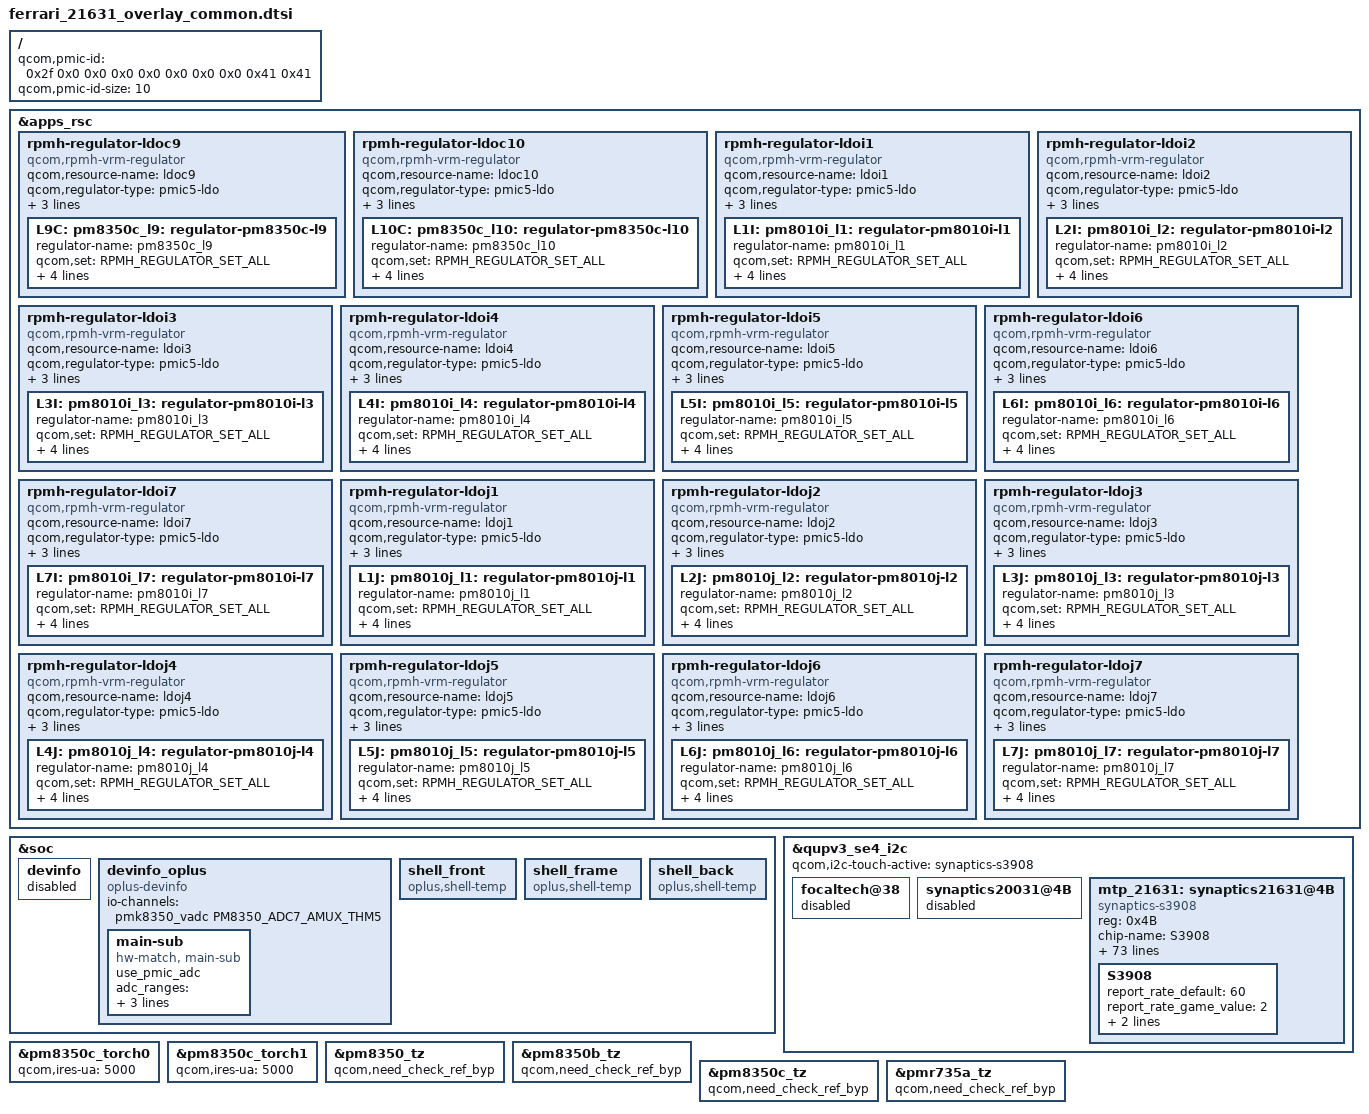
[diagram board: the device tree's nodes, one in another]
/* Waipio configurations for PM8010I and PM8010J connected via SPMI */

#include <dt-bindings/regulator/qcom,rpmh-regulator-levels.h>

/ {
	qcom,pmic-id = <0x2f 0x0 0x0 0x0 0x0 0x0 0x0 0x0 0x41 0x41>;
	qcom,pmic-id-size = <10>;
};

&apps_rsc {

    rpmh-regulator-ldoc9 {
		compatible = "qcom,rpmh-vrm-regulator";
		qcom,resource-name = "ldoc9";
		qcom,regulator-type = "pmic5-ldo";
		qcom,supported-modes =
			<RPMH_REGULATOR_MODE_LPM
			 RPMH_REGULATOR_MODE_HPM>;
		qcom,mode-threshold-currents = <0 10000>;
		L9C: pm8350c_l9: regulator-pm8350c-l9 {
			regulator-name = "pm8350c_l9";
			qcom,set = <RPMH_REGULATOR_SET_ALL>;
			regulator-min-microvolt = <2800000>;
			regulator-max-microvolt = <3008000>;
			qcom,init-voltage = <2800000>;
			qcom,init-mode = <RPMH_REGULATOR_MODE_HPM>;
		};
	};

    rpmh-regulator-ldoc10 {
		compatible = "qcom,rpmh-vrm-regulator";
		qcom,resource-name = "ldoc10";
		qcom,regulator-type = "pmic5-ldo";
		qcom,supported-modes =
			<RPMH_REGULATOR_MODE_LPM
			 RPMH_REGULATOR_MODE_HPM>;
		qcom,mode-threshold-currents = <0 30000>;
		L10C: pm8350c_l10: regulator-pm8350c-l10 {
			regulator-name = "pm8350c_l10";
			qcom,set = <RPMH_REGULATOR_SET_ALL>;
			regulator-min-microvolt = <1104000>;
			regulator-max-microvolt = <1104000>;
			qcom,init-voltage = <1104000>;
			qcom,init-mode = <RPMH_REGULATOR_MODE_HPM>;
		};
	};

	rpmh-regulator-ldoi1 {
	    compatible = "qcom,rpmh-vrm-regulator";
	    qcom,resource-name = "ldoi1";
	    qcom,regulator-type = "pmic5-ldo";
	    qcom,supported-modes =
	        <RPMH_REGULATOR_MODE_LPM
	         RPMH_REGULATOR_MODE_HPM>;
	    qcom,mode-threshold-currents = <0 30000>;
	    L1I: pm8010i_l1: regulator-pm8010i-l1 {
	        regulator-name = "pm8010i_l1";
	        qcom,set = <RPMH_REGULATOR_SET_ALL>;
	        regulator-min-microvolt = <1104000>;
	        regulator-max-microvolt = <1204000>;
	        qcom,init-voltage = <1150000>;
	        qcom,init-mode = <RPMH_REGULATOR_MODE_HPM>;
	    };
	};

	rpmh-regulator-ldoi2 {
		compatible = "qcom,rpmh-vrm-regulator";
		qcom,resource-name = "ldoi2";
		qcom,regulator-type = "pmic5-ldo";
		qcom,supported-modes =
			<RPMH_REGULATOR_MODE_LPM
			 RPMH_REGULATOR_MODE_HPM>;
		qcom,mode-threshold-currents = <0 30000>;
		L2I: pm8010i_l2: regulator-pm8010i-l2 {
			regulator-name = "pm8010i_l2";
			qcom,set = <RPMH_REGULATOR_SET_ALL>;
			regulator-min-microvolt = <1056000>;
			regulator-max-microvolt = <1260000>;
			qcom,init-voltage = <1056000>;
			qcom,init-mode = <RPMH_REGULATOR_MODE_HPM>;
		};
	};

	rpmh-regulator-ldoi3 {
		compatible = "qcom,rpmh-vrm-regulator";
		qcom,resource-name = "ldoi3";
		qcom,regulator-type = "pmic5-ldo";
		qcom,supported-modes =
			<RPMH_REGULATOR_MODE_LPM
			 RPMH_REGULATOR_MODE_HPM>;
		qcom,mode-threshold-currents = <0 10000>;
		L3I: pm8010i_l3: regulator-pm8010i-l3 {
			regulator-name = "pm8010i_l3";
			qcom,set = <RPMH_REGULATOR_SET_ALL>;
			regulator-min-microvolt = <2700000>;
			regulator-max-microvolt = <2904000>;
			qcom,init-voltage = <2800000>;
			qcom,init-mode = <RPMH_REGULATOR_MODE_HPM>;
		};
	};

	rpmh-regulator-ldoi4 {
		compatible = "qcom,rpmh-vrm-regulator";
		qcom,resource-name = "ldoi4";
		qcom,regulator-type = "pmic5-ldo";
		qcom,supported-modes =
			<RPMH_REGULATOR_MODE_LPM
			 RPMH_REGULATOR_MODE_HPM>;
		qcom,mode-threshold-currents = <0 10000>;
		L4I: pm8010i_l4: regulator-pm8010i-l4 {
			regulator-name = "pm8010i_l4";
			qcom,set = <RPMH_REGULATOR_SET_ALL>;
			regulator-min-microvolt = <2800000>;
			regulator-max-microvolt = <3304000>;
			qcom,init-voltage = <3150000>;
			qcom,init-mode = <RPMH_REGULATOR_MODE_HPM>;
		};
	};
	rpmh-regulator-ldoi5 {
	    compatible = "qcom,rpmh-vrm-regulator";
	    qcom,resource-name = "ldoi5";
	    qcom,regulator-type = "pmic5-ldo";
	    qcom,supported-modes =
	        <RPMH_REGULATOR_MODE_LPM
	         RPMH_REGULATOR_MODE_HPM>;
	    qcom,mode-threshold-currents = <0 10000>;
	    L5I: pm8010i_l5: regulator-pm8010i-l5 {
	        regulator-name = "pm8010i_l5";
	        qcom,set = <RPMH_REGULATOR_SET_ALL>;
	        regulator-min-microvolt = <1800000>;
	        regulator-max-microvolt = <2800000>;
	        qcom,init-voltage = <1800000>;
	        qcom,init-mode = <RPMH_REGULATOR_MODE_HPM>;
	    };
	};

	rpmh-regulator-ldoi6 {
		compatible = "qcom,rpmh-vrm-regulator";
		qcom,resource-name = "ldoi6";
		qcom,regulator-type = "pmic5-ldo";
		qcom,supported-modes =
			<RPMH_REGULATOR_MODE_LPM
			 RPMH_REGULATOR_MODE_HPM>;
		qcom,mode-threshold-currents = <0 10000>;
		L6I: pm8010i_l6: regulator-pm8010i-l6 {
			regulator-name = "pm8010i_l6";
			qcom,set = <RPMH_REGULATOR_SET_ALL>;
			regulator-min-microvolt = <2800000>;
			regulator-max-microvolt = <3304000>;
			qcom,init-voltage = <3150000>;
			qcom,init-mode = <RPMH_REGULATOR_MODE_HPM>;
		};
	};

	rpmh-regulator-ldoi7 {
		compatible = "qcom,rpmh-vrm-regulator";
		qcom,resource-name = "ldoi7";
		qcom,regulator-type = "pmic5-ldo";
		qcom,supported-modes =
			<RPMH_REGULATOR_MODE_LPM
			 RPMH_REGULATOR_MODE_HPM>;
		qcom,mode-threshold-currents = <0 10000>;
		L7I: pm8010i_l7: regulator-pm8010i-l7 {
			regulator-name = "pm8010i_l7";
			qcom,set = <RPMH_REGULATOR_SET_ALL>;
			regulator-min-microvolt = <1800000>;
			regulator-max-microvolt = <2960000>;
			qcom,init-voltage = <1800000>;
			qcom,init-mode = <RPMH_REGULATOR_MODE_HPM>;
		};
	};

	rpmh-regulator-ldoj1 {
		compatible = "qcom,rpmh-vrm-regulator";
		qcom,resource-name = "ldoj1";
		qcom,regulator-type = "pmic5-ldo";
		qcom,supported-modes =
			<RPMH_REGULATOR_MODE_LPM
			 RPMH_REGULATOR_MODE_HPM>;
		qcom,mode-threshold-currents = <0 30000>;
		L1J: pm8010j_l1: regulator-pm8010j-l1 {
			regulator-name = "pm8010j_l1";
			qcom,set = <RPMH_REGULATOR_SET_ALL>;
			regulator-min-microvolt = <1104000>;
			regulator-max-microvolt = <1204000>;
			qcom,init-voltage = <1104000>;
			qcom,init-mode = <RPMH_REGULATOR_MODE_HPM>;
		};
	};

	rpmh-regulator-ldoj2 {
		compatible = "qcom,rpmh-vrm-regulator";
		qcom,resource-name = "ldoj2";
		qcom,regulator-type = "pmic5-ldo";
		qcom,supported-modes =
			<RPMH_REGULATOR_MODE_LPM
			 RPMH_REGULATOR_MODE_HPM>;
		qcom,mode-threshold-currents = <0 30000>;
		L2J: pm8010j_l2: regulator-pm8010j-l2 {
			regulator-name = "pm8010j_l2";
			qcom,set = <RPMH_REGULATOR_SET_ALL>;
			regulator-min-microvolt = <800000>;
			regulator-max-microvolt = <1056000>;
			qcom,init-voltage = <810000>;
			qcom,init-mode = <RPMH_REGULATOR_MODE_HPM>;
		};
	};

	rpmh-regulator-ldoj3 {
		compatible = "qcom,rpmh-vrm-regulator";
		qcom,resource-name = "ldoj3";
		qcom,regulator-type = "pmic5-ldo";
		qcom,supported-modes =
			<RPMH_REGULATOR_MODE_LPM
			 RPMH_REGULATOR_MODE_HPM>;
		qcom,mode-threshold-currents = <0 10000>;
		L3J: pm8010j_l3: regulator-pm8010j-l3 {
			regulator-name = "pm8010j_l3";
			qcom,set = <RPMH_REGULATOR_SET_ALL>;
			regulator-min-microvolt = <1800000>;
			regulator-max-microvolt = <2904000>;
			qcom,init-voltage = <2800000>;
			qcom,init-mode = <RPMH_REGULATOR_MODE_HPM>;
		};
	};

	rpmh-regulator-ldoj4 {
		compatible = "qcom,rpmh-vrm-regulator";
		qcom,resource-name = "ldoj4";
		qcom,regulator-type = "pmic5-ldo";
		qcom,supported-modes =
			<RPMH_REGULATOR_MODE_LPM
			 RPMH_REGULATOR_MODE_HPM>;
		qcom,mode-threshold-currents = <0 10000>;
		L4J: pm8010j_l4: regulator-pm8010j-l4 {
			regulator-name = "pm8010j_l4";
			qcom,set = <RPMH_REGULATOR_SET_ALL>;
			regulator-min-microvolt = <2800000>;
			regulator-max-microvolt = <3008000>;
			qcom,init-voltage = <2904000>;
			qcom,init-mode = <RPMH_REGULATOR_MODE_HPM>;
		};
	};

	rpmh-regulator-ldoj5 {
		compatible = "qcom,rpmh-vrm-regulator";
		qcom,resource-name = "ldoj5";
		qcom,regulator-type = "pmic5-ldo";
		qcom,supported-modes =
			<RPMH_REGULATOR_MODE_LPM
			 RPMH_REGULATOR_MODE_HPM>;
		qcom,mode-threshold-currents = <0 10000>;
		L5J: pm8010j_l5: regulator-pm8010j-l5 {
			regulator-name = "pm8010j_l5";
			qcom,set = <RPMH_REGULATOR_SET_ALL>;
			regulator-min-microvolt = <1800000>;
			regulator-max-microvolt = <2800000>;
			qcom,init-voltage = <1800000>;
			qcom,init-mode = <RPMH_REGULATOR_MODE_HPM>;
		};
	};

	rpmh-regulator-ldoj6 {
		compatible = "qcom,rpmh-vrm-regulator";
		qcom,resource-name = "ldoj6";
		qcom,regulator-type = "pmic5-ldo";
		qcom,supported-modes =
			<RPMH_REGULATOR_MODE_LPM
			 RPMH_REGULATOR_MODE_HPM>;
		qcom,mode-threshold-currents = <0 10000>;
		L6J: pm8010j_l6: regulator-pm8010j-l6 {
			regulator-name = "pm8010j_l6";
			qcom,set = <RPMH_REGULATOR_SET_ALL>;
			regulator-min-microvolt = <2800000>;
			regulator-max-microvolt = <2800000>;
			qcom,init-voltage = <2800000>;
			qcom,init-mode = <RPMH_REGULATOR_MODE_HPM>;
		};
	};

	rpmh-regulator-ldoj7 {
		compatible = "qcom,rpmh-vrm-regulator";
		qcom,resource-name = "ldoj7";
		qcom,regulator-type = "pmic5-ldo";
		qcom,supported-modes =
			<RPMH_REGULATOR_MODE_LPM
			 RPMH_REGULATOR_MODE_HPM>;
		qcom,mode-threshold-currents = <0 10000>;
		L7J: pm8010j_l7: regulator-pm8010j-l7 {
			regulator-name = "pm8010j_l7";
			qcom,set = <RPMH_REGULATOR_SET_ALL>;
			regulator-min-microvolt = <2800000>;
			regulator-max-microvolt = <3304000>;
			qcom,init-voltage = <2800000>;
			qcom,init-mode = <RPMH_REGULATOR_MODE_HPM>;
		};
	};
};
&soc {
    devinfo {
        status = "disabled";
    };

	devinfo_oplus {
		compatible = "oplus-devinfo";

		//pinctrl-names = "active", "sleep";
		//pinctrl-0 = <&hw_id_active>;
		//pinctrl-1 = <&hw_id_sleep>;

		io-channels= <&pmk8350_vadc PM8350_ADC7_AMUX_THM5>;
		io-channel-names= "vph_pwr_voltage_sub";

		main-sub {
			compatible = "hw-match, main-sub";
			use_pmic_adc;
			adc_ranges = <0 80
					81 180
					181 300
					301 420
					421 550
					551 650
					651 760
					761 850
					851 950
					951 1050
					1051 1150
					1151 1300>;
			aboard-patterns = <0 0>;

			/*main board*/
			match-projects = <21631 0x216AC>;
		};
	};

	//#ifdef OPLUS_FEATURE_THERMAL_HORAE
	shell_front {
			compatible = "oplus,shell-temp";
	};

	shell_frame {
			compatible = "oplus,shell-temp";
	};

	shell_back {
			compatible = "oplus,shell-temp";
	};
	//#endif

};
&qupv3_se4_i2c {
	qcom,i2c-touch-active = "synaptics-s3908";

	focaltech@38 {
		status = "disabled";
	};

	synaptics20031@4B {
		status = "disabled";
	};

	mtp_21631:synaptics21631@4B {
		compatible = "synaptics-s3908";
		reg = <0x4B>;
		chip-name = "S3908";

		/* Interrupt && Irq-gpio */
		interrupt-parent = <&tlmm>;
		interrupts = <21 0x2008>;

		/* Power Config */
		//enable2v8_gpio = <&tlmm 26 0x1>;
		enable1v8_gpio = <&tlmm 97 0x1>;
		vdd_2v8-supply = <&L3C>;
		vcc_1v8-supply = <&L4H>;
		vdd_2v8_volt = <3008000>;

		/* Other HW Resource */
		irq-gpio = <&tlmm 21 0x2008>;
		reset-gpio = <&tlmm 20 0x1>;
		pinctrl-names = "default";
		pinctrl-0 = <&ts_int_active &ts_reset_active>;

		touchpanel,max-num-support = <10>;
		touchpanel,tx-rx-num = <17 38>;
		earsense,tx-rx-num = <17 18>;
		touchpanel,panel-coords = <5760 12864>;
		touchpanel,display-coords = <1440 3216>;
		touchpanel,touchmajor-limit = <256 256>;
		touchpanel,int-mode = <1>; /*0: interrupt and disable, 1:interrupt and not disable*/
		touchpanel,curved-size = <45>;


		prevention,curved_screen_V2;
		prevention,grip_disable_level = <6>;
		prevention,updelay_time_ms = <30>;
		prevention,makeup_cnt_weight = <4 1 2 2 2>;
		prevention,large_corner_range = <600 1500>;
		prevention,large_corner_judge_condition = <500 100 600 6 6>;
		prevention,trx_reject_condition = <8 7 7>;
		prevention,trx_strict_reject_condition = <8 5 5>;
		prevention,large_judge_time_ms = <500 50 40>;
		prevention,large_exit_condition = <8 8 2>;
		prevention,single_channel_width = <160 160>;
		prevention,normal_tap_condition = <10 300>;
		prevention,long_edge_condition = <230 90 180 80>;
		prevention,long_strict_edge_condition = <160 60>;
		prevention,long_fingerhold_condition = <50 6 4 4>;
		prevention,short_edge_condition = <200 90 180 80>;
		prevention,short_strict_edge_condition = <160 60>;
		prevention,large_strict_exit_condition = <2 2>;
		prevention,top_corner_config = <280 800 240>;
		prevention,edge_swipe_config = <150 400>;

		touchpanel,smooth-level = <0 1 2 4 7 9>;
		touchpanel,smooth-level-charging = <0 2 4 7 8 9>;
		touchpanel,sensitive-level = <0 70 55 40 25 10>;
		touchpanel,single-optimized-time = <8>;
		touchpanel,high-frame-rate-time = <60>;

		end_stretch_value = <480 250 16 16>;

		touchpanel,tp_ic_type = <2>;
		panel_type = <8 8>;
		// type of tp_dev ,TP-SAMSUNG = 8;
		firmware_name = "SS", "SS";
		platform_support_project = <20031 21631 0x216AC>;
		platform_support_project_dir = <21631 21631 21631>;
		platform_support_project_commandline = "mdss_dsi_oplus20031_samsung_1440_3216_dsc_cmd","mdss_dsi_oplus21631_samsung_1440_3216_dsc_cmd_t0";

		/* SW Support Feature Control */
		black_gesture_support;
		sportify_aod_gesture_support;
		//fw_edge_limit_support;
		pressure_report_support;
		charger_pump_support;
		game_switch_support;
		smart_gesture_support;
		fw_update_app_support;
		fingerprint_underscreen_support;
		freq_hop_simulate_support;
		report_flow_unlock_support;
		screenoff_fingerprint_info_support;
		irq_need_dev_resume_ok;
		//firmware_in_dts;
		enable_point_auto_change;
		report_rate_white_list_support;
		kernel_grip_support;
		//grip_no_driver_support;
		health_monitor_support;
		black_gesture_indep_support;
		algorithm_support;

		/*
		 *Virtual Key Config:
		 *1:touchpanel,button-type: <virtualkey_type  supportted_button-map>
		 *virtualkey_type:
		 *Type 1: using board_properties
		 *Type 2: using same IC (button zone&& touch zone are seprate)
		 *Type 3: using diffrent IC (button zone&& touch zone are seprate)
		 *Type 4: No need of virtual key process
		 *supportted_button-map:select|menu|home|back
		 *
		 *2:touchpanel,button-map
		 *type (X1,Y1)(X2,Y2)(X3,Y3)(Width_X,Hight_Y)--Only when button-type is 0
		 */
		touchpanel,button-type = <4>;
		touchpanel.button-TRx = <0 0>;

		S3908 {
			report_rate_default = <60>;
			report_rate_game_value = <2>;
			default_gesture_mask = <8191>;
			fwupdate_bootloader = <1>;
		};
	};
//#endif /*OPLUS_FEATURE_TP_BASIC*/
};
#include "tp/mtp21631-s3908-firmware.dtsi"
//#endif /*OPLUS_FEATURE_TP_BASIC*/


&pm8350c_torch0 {
	qcom,ires-ua = <5000>;
};

&pm8350c_torch1 {
	qcom,ires-ua = <5000>;
};

//#ifdef OPLUS_FEATURE_CHG_BASIC
&pm8350_tz {
	qcom,need_check_ref_byp;
};

&pm8350b_tz {
	qcom,need_check_ref_byp;
};

&pm8350c_tz {
	qcom,need_check_ref_byp;
};

&pmr735a_tz {
	qcom,need_check_ref_byp;
};
//#endif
